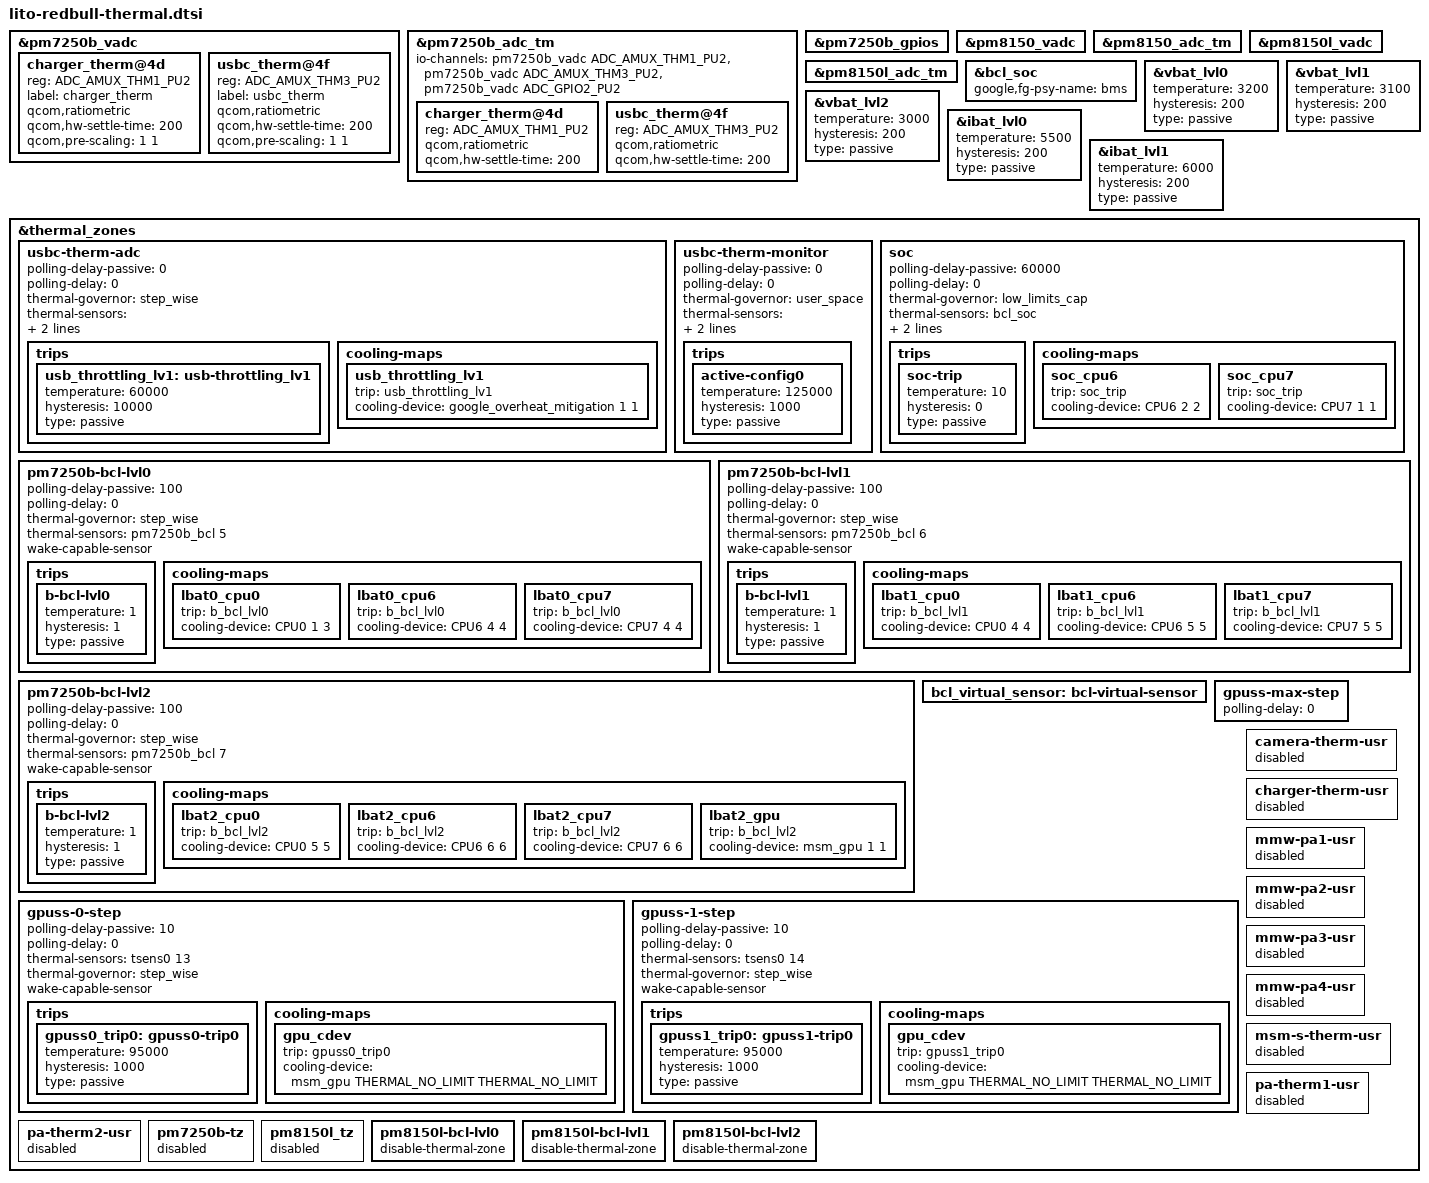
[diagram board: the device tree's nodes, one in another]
// SPDX-License-Identifier: GPL-2.0
/* Copyright (c) 2019, The Linux Foundation. All rights reserved.
 *
 * This program is free software; you can redistribute it and/or modify
 * it under the terms of the GNU General Public License version 2 and
 * only version 2 as published by the Free Software Foundation.
 *
 * This program is distributed in the hope that it will be useful,
 * but WITHOUT ANY WARRANTY; without even the implied warranty of
 * MERCHANTABILITY or FITNESS FOR A PARTICULAR PURPOSE.  See the
 * GNU General Public License for more details.
 */

&pm7250b_vadc {
	/* Disable redundant QCT default settings */
	/delete-node/ bmr_s_therm;
	/delete-node/ charger_skin_therm@4d;
	/delete-node/ conn_therm@4f;
	/delete-node/ bmr_w_therm@53;
	/delete-node/ camera_flash_therm@55;

	charger_therm@4d {
		reg = <ADC_AMUX_THM1_PU2>;
		label = "charger_therm";
		qcom,ratiometric;
		qcom,hw-settle-time = <200>;
		qcom,pre-scaling = <1 1>;
	};

	usbc_therm@4f {
		reg = <ADC_AMUX_THM3_PU2>;
		label = "usbc_therm";
		qcom,ratiometric;
		qcom,hw-settle-time = <200>;
		qcom,pre-scaling = <1 1>;
	};
};

&pm7250b_adc_tm {
	io-channels = <&pm7250b_vadc ADC_AMUX_THM1_PU2>,
			<&pm7250b_vadc ADC_AMUX_THM3_PU2>,
			<&pm7250b_vadc ADC_GPIO2_PU2>;

	/* Disable redundant QCT default settings */
	/delete-node/ charger_skin_therm@4d;
	/delete-node/ bmr_w_therm@53;
	/delete-node/ bmr_s_therm@54;
	/delete-node/ camera_flash_therm@55;

	/* Channel nodes */
	charger_therm@4d {
		reg = <ADC_AMUX_THM1_PU2>;
		qcom,ratiometric;
		qcom,hw-settle-time = <200>;
	};

	usbc_therm@4f {
		reg = <ADC_AMUX_THM3_PU2>;
		qcom,ratiometric;
		qcom,hw-settle-time = <200>;
	};
};

/* Disable redundant QCT default settings */
&pm7250b_gpios {
	/delete-node/ bmr_s_therm;
};

&pm8150_vadc {
	/delete-node/ pa_therm1@4d;
	/delete-node/ bmr_e_therm@4e;
};

&pm8150_adc_tm {
	/delete-node/ pa_therm1@4d;
	/delete-node/ bmr_e_therm@4e;
};

&pm8150l_vadc {
	/delete-node/ pa_therm2@4d;
	/delete-node/ msm_skin_therm1@4e;
	/delete-node/ bmr_n_therm@4f;
};

&pm8150l_adc_tm {
	/delete-node/ pa_therm2@4d;
	/delete-node/ msm_skin_therm1@4e;
	/delete-node/ bmr_n_therm@4f;
};

&bcl_soc {
	google,fg-psy-name = "bms";
};

&vbat_lvl0 {
	temperature = <3200>;
	hysteresis = <200>;
	type = "passive";
};

&vbat_lvl1 {
	temperature = <3100>;
	hysteresis = <200>;
	type = "passive";
};

&vbat_lvl2 {
	temperature = <3000>;
	hysteresis = <200>;
	type = "passive";
};

&ibat_lvl0 {
	temperature = <5500>;
	hysteresis = <200>;
	type = "passive";
};

&ibat_lvl1 {
	temperature = <6000>;
	hysteresis = <200>;
	type = "passive";
};

&thermal_zones {
	/* Bring up common thermal zones for Redfin and Bramble */
	usbc-therm-adc {
		polling-delay-passive = <0>;
		polling-delay = <0>;
		thermal-governor = "step_wise";
		thermal-sensors = <&pm7250b_adc_tm ADC_AMUX_THM3_PU2>;
		wake-capable-sensor;
		trips {
			usb_throttling_lv1: usb-throttling_lv1 {
				temperature = <60000>;
				hysteresis = <10000>;
				type = "passive";
			};
		};
		cooling-maps {
			usb_throttling_lv1 {
				trip = <&usb_throttling_lv1>;
				cooling-device =
					<&google_overheat_mitigation 1 1>;
			};
		};
	};

	usbc-therm-monitor {
		polling-delay-passive = <0>;
		polling-delay = <0>;
		thermal-governor = "user_space";
		thermal-sensors = <&pm7250b_adc_tm ADC_AMUX_THM3_PU2>;
		wake-capable-sensor;
		trips {
			active-config0 {
				temperature = <125000>;
				hysteresis = <1000>;
				type = "passive";
			};
		};
	};

	soc {
		polling-delay-passive = <60000>;
		polling-delay = <0>;
		thermal-governor = "low_limits_cap";
		thermal-sensors = <&bcl_soc>;
		wake-capable-sensor;
		tracks-low;
		trips {
			soc-trip {
				temperature = <10>;
				hysteresis = <0>;
				type = "passive";
			};
		};
		cooling-maps {
			soc_cpu6 {
				trip = <&soc_trip>;
				cooling-device =
					<&CPU6 2 2>;
			};
			soc_cpu7 {
				trip = <&soc_trip>;
				cooling-device =
					<&CPU7 1 1>;
			};
		};
	};

	pm7250b-bcl-lvl0 {
		polling-delay-passive = <100>;
		polling-delay = <0>;
		thermal-governor = "step_wise";
		thermal-sensors = <&pm7250b_bcl 5>;
		wake-capable-sensor;
		trips {
			b-bcl-lvl0 {
				temperature = <1>;
				hysteresis = <1>;
				type = "passive";
			};
		};
		cooling-maps {
			lbat0_cpu0 {
				trip = <&b_bcl_lvl0>;
				cooling-device =
					<&CPU0 1 3>;
			};
			lbat0_cpu6 {
				trip = <&b_bcl_lvl0>;
				cooling-device =
					<&CPU6 4 4>;
			};
			lbat0_cpu7 {
				trip = <&b_bcl_lvl0>;
				cooling-device =
					<&CPU7 4 4>;
			};
		};
	};

	pm7250b-bcl-lvl1 {
		polling-delay-passive = <100>;
		polling-delay = <0>;
		thermal-governor = "step_wise";
		thermal-sensors = <&pm7250b_bcl 6>;
		wake-capable-sensor;
		trips {
			b-bcl-lvl1 {
				temperature = <1>;
				hysteresis = <1>;
				type = "passive";
			};
		};
		cooling-maps {
			lbat1_cpu0 {
				trip = <&b_bcl_lvl1>;
				cooling-device =
					<&CPU0 4 4>;
			};
			lbat1_cpu6 {
				trip = <&b_bcl_lvl1>;
				cooling-device =
					<&CPU6 5 5>;
			};
			lbat1_cpu7 {
				trip = <&b_bcl_lvl1>;
				cooling-device =
					<&CPU7 5 5>;
			};
		};
	};

	pm7250b-bcl-lvl2 {
		polling-delay-passive = <100>;
		polling-delay = <0>;
		thermal-governor = "step_wise";
		thermal-sensors = <&pm7250b_bcl 7>;
		wake-capable-sensor;
		trips {
			b-bcl-lvl2 {
				temperature = <1>;
				hysteresis = <1>;
				type = "passive";
			};
		};
		cooling-maps {
			lbat2_cpu0 {
				trip = <&b_bcl_lvl2>;
				cooling-device =
					<&CPU0 5 5>;
			};
			lbat2_cpu6 {
				trip = <&b_bcl_lvl2>;
				cooling-device =
					<&CPU6 6 6>;
			};
			lbat2_cpu7 {
				trip = <&b_bcl_lvl2>;
				cooling-device =
					<&CPU7 6 6>;
			};
			lbat2_gpu {
				trip = <&b_bcl_lvl2>;
				cooling-device =
					<&msm_gpu 1 1>;
			};
		};
	};

	bcl_virtual_sensor: bcl-virtual-sensor {
	};

	gpuss-max-step {
		polling-delay = <0>;
	};

	gpuss-0-step {
		polling-delay-passive = <10>;
		polling-delay = <0>;
		thermal-sensors = <&tsens0 13>;
		thermal-governor = "step_wise";
		wake-capable-sensor;
		trips {
			gpuss0_trip0: gpuss0-trip0 {
				temperature = <95000>;
				hysteresis = <1000>;
				type = "passive";
			};
		};
		cooling-maps {
			gpu_cdev {
				trip = <&gpuss0_trip0>;
				cooling-device = <&msm_gpu THERMAL_NO_LIMIT
							THERMAL_NO_LIMIT>;
			};
		};
	};

	gpuss-1-step {
		polling-delay-passive = <10>;
		polling-delay = <0>;
		thermal-sensors = <&tsens0 14>;
		thermal-governor = "step_wise";
		wake-capable-sensor;
		trips {
			gpuss1_trip0: gpuss1-trip0 {
				temperature = <95000>;
				hysteresis = <1000>;
				type = "passive";
			};
		};
		cooling-maps {
			gpu_cdev {
				trip = <&gpuss1_trip0>;
				cooling-device = <&msm_gpu THERMAL_NO_LIMIT
							THERMAL_NO_LIMIT>;
			};
		};
	};

	/* Remove redundant QCT thermal zones */
	camera-therm-usr {
		status = "disabled";
	};

	charger-therm-usr {
		status = "disabled";
	};

	mmw-pa1-usr {
		status = "disabled";
	};

	mmw-pa2-usr {
		status = "disabled";
	};

	mmw-pa3-usr {
		status = "disabled";
	};

	mmw-pa4-usr {
		status = "disabled";
	};

	msm-s-therm-usr {
		status = "disabled";
	};

	pa-therm1-usr {
		status = "disabled";
	};

	pa-therm2-usr {
		status = "disabled";
	};

	pm7250b-tz {
		status = "disabled";
	};

	pm8150l_tz {
		status = "disabled";
	};

	/* Disable PM8150l BCL */
	pm8150l-bcl-lvl0 {
		disable-thermal-zone;
	};

	pm8150l-bcl-lvl1 {
		disable-thermal-zone;
	};

	pm8150l-bcl-lvl2 {
		disable-thermal-zone;
	};
};
